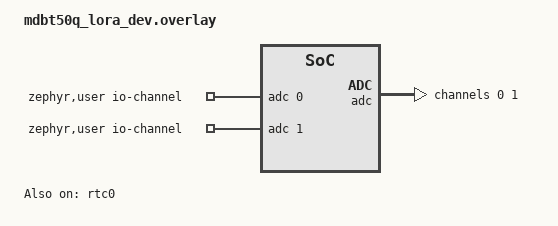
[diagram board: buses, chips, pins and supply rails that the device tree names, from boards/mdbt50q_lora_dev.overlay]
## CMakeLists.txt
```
cmake_minimum_required(VERSION 3.20.0)

find_package(Zephyr REQUIRED HINTS $ENV{ZEPHYR_BASE})
project(nrf52840_rtos_6sens)

FILE(GLOB app_sources src/*.c)
target_sources(app PRIVATE ${app_sources})
```

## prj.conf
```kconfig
# Debugger Support
CONFIG_UART_CONSOLE=n
CONFIG_CONSOLE=y
CONFIG_SERIAL=y

# RTT Segger Support
CONFIG_RTT_CONSOLE=y
CONFIG_USE_SEGGER_RTT=y
CONFIG_LOG_BACKEND_RTT=y

# Communication Bus Support
CONFIG_GPIO=y
CONFIG_SPI=y
CONFIG_I2C=y

# Hardware Support
CONFIG_ADC=y
CONFIG_SENSOR=y

# RTC Support
CONFIG_RTC=y
CONFIG_COUNTER=y
CONFIG_CLOCK_CONTROL=y
CONFIG_COUNTER_MAXIM_DS3231=y

# LoRa Support
CONFIG_LORA=y

# LoRaWAN Support
CONFIG_LORAWAN=y
CONFIG_HAS_SEMTECH_LORAMAC=y
CONFIG_LORAMAC_REGION_EU868=y
CONFIG_LORAWAN_SYSTEM_MAX_RX_ERROR=100

# Flash Memory Support (MX25R64 and partion flash memory of MDBT50Q)
# Flash Memory Support
CONFIG_FLASH=y
CONFIG_FLASH_MAP=y
CONFIG_MPU_ALLOW_FLASH_WRITE=y
CONFIG_NORDIC_QSPI_NOR=y

# Stack Support
CONFIG_MAIN_STACK_SIZE=2048
CONFIG_SYSTEM_WORKQUEUE_STACK_SIZE=2048

# Random Number Generation Support
CONFIG_TEST_RANDOM_GENERATOR=y
CONFIG_PRINTK=y
CONFIG_CBPRINTF_FP_SUPPORT=y
CONFIG_NEWLIB_LIBC=y
CONFIG_NEWLIB_LIBC_FLOAT_PRINTF=y
CONFIG_FP_SOFTABI=y
```

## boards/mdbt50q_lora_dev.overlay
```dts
/*
 * Copyright (c) 2025
 * Regis Rousseau
 * Univ Lyon, INSA Lyon, Inria, CITI, EA3720
 * SPDX-License-Identifier: Apache-2.0
 */

/* VBAT battery voltage monitoring and Sismic sensor analog value conversion */
/ {
	zephyr,user {
		io-channels = <&adc 0>,<&adc 1>;
	};
};

/* enable the corresponding ADC, with the correct configuration */
&adc {
	#address-cells = <1>;
	#size-cells = <0>;
	status = "okay";

	/* external ADC channnel AIN0 of MDBT50Q, Port P0.02 on schematic for geophone*/
	channel@0 {
		reg = <0>;											/* channel 0 of the ADC */
		zephyr,gain = "ADC_GAIN_1_6";						/* attenuated by 6 (x1/6) */
		zephyr,reference = "ADC_REF_INTERNAL";				/* reference voltage +0.6 */
		zephyr,acquisition-time = <ADC_ACQ_TIME_DEFAULT>;	/* 10us */
		zephyr,input-positive = <NRF_SAADC_AIN0>;			/* P0.02 for nRF52xx */
		zephyr,resolution = <12>;
	};
	
	/* external ADC channnel AIN1 of MDBT50Q, Port P0.03 on schematic for battery*/
	channel@1 {
		reg = <1>;											/* channel 0 of the ADC */
		zephyr,gain = "ADC_GAIN_1_6";						/* attenuated by 6 (x1/6) */
		zephyr,reference = "ADC_REF_INTERNAL";				/* reference voltage +0.6 */
		zephyr,acquisition-time = <ADC_ACQ_TIME_DEFAULT>;	/* 10us */
		zephyr,input-positive = <NRF_SAADC_AIN1>;			/* P0.03 for nRF52xx */
		zephyr,resolution = <12>;
	};
};

&rtc0 {
	status = "okay";
};
```

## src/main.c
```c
/*
 * Copyright (c) 2025
 * Regis Rousseau
 * Univ Lyon, INSA Lyon, Inria, CITI, EA3720
 * SPDX-License-Identifier: Apache-2.0
 */

//  ========== includes ====================================================================
#include <zephyr/kernel.h>
#include "app_sensors.h"
#include "app_adc.h"
#include "app_eeprom.h"
#include "app_rtc.h"
#include <stdbool.h>
#include <stdio.h>

//  ========== defines =====================================================================
#define STACK_SIZE			2048
#define PRIORITY_RTC		2
#define PRIORITY_LORAWAN	3

//  ========== globals =====================================================================
// define GPIO specifications for the LEDs used to indicate transmission (TX) and reception (RX)
static const struct gpio_dt_spec led_tx = GPIO_DT_SPEC_GET(LED_TX, gpios);
static const struct gpio_dt_spec led_rx = GPIO_DT_SPEC_GET(LED_RX, gpios);

static void dl_callback(uint8_t port, bool data_pending,
			int16_t rssi, int8_t snr,
			uint8_t len, const uint8_t *hex_data)
{
	printk("Port %d, Pending %d, RSSI %ddB, SNR %ddBm\n", port, data_pending, rssi, snr);
}

// thread to have a periodic sync
bool rtc_thread_flag = true;
void rtc_thread_func(void)
{
	printk("periodic sync thread started\n");

	const struct device *rtc_dev = DEVICE_DT_GET(DT_NODELABEL(rtc0));
	const struct device *ds3231_dev = DEVICE_DT_GET_ONE(maxim_ds3231);

	while (rtc_thread_flag == true) {
        printk("performing periodic action\n");
        //(void)app_rtc_periodic_sync(rtc_dev);
		(void)app_ds3231_periodic_sync(ds3231_dev);
        k_sleep(K_SECONDS(60));		
	}
}
K_THREAD_DEFINE(rtc_thread_id, STACK_SIZE, rtc_thread_func, NULL, NULL, NULL, PRIORITY_RTC, 0, 0);

// thread to send environment value when no activity
bool lorawan_thread_flag = true;
void lorawan_thread_func(void)
{
	printk("LoRaWAN thread started\n");
    while (lorawan_thread_flag == true) {
        printk("performing periodic action\n");
		// perform your task: get battery level, temperature and humidity
        (void)app_sensors_handler();	
        k_sleep(K_SECONDS(60));		// sleep for 1 min -> test
    }
}
K_THREAD_DEFINE(lorawan_thread_id, STACK_SIZE, lorawan_thread_func, NULL, NULL, NULL, PRIORITY_LORAWAN, 0, 0);

static void lorwan_datarate_changed(enum lorawan_datarate dr)
{
	uint8_t unused, max_size;

	lorawan_get_payload_sizes(&unused, &max_size);
	printk("New Datarate: DR_%d, Max Payload %d\n", dr, max_size);
}

//  ========== main ========================================================================
int8_t main(void)
{
	const struct device *dev;
	int8_t ret;

	printk("Initializtion of all Hardware Devices\n");

	// initialize ADC device
	ret = app_nrf52_adc_init();
	if (ret != 1) {
		printk("failed to initialize ADC device\n");
		return 0;
	}

	// initialize partition flash memory
	ret = app_flash_init();
	if (ret != 1) {
		printk("failed to initialize internal Flash device\n");
		return 0;
	}

	// initialize the EEPROM device
	const struct device *eeprom_dev = DEVICE_DT_GET(SPI_FLASH_DEVICE);
	ret = app_eeprom_init(eeprom_dev);
	if (ret != 1) {
		printk("failed to initialize QSPI flash device\n");
		return 0;
	}

	// initialize DS3231 RTC device via I2C (Pins: SDA -> P0.09, SCL -> P0.0)
	const struct device *rtc_dev = app_rtc_init();
    if (!rtc_dev) {
        printk("failed to initialize RTC device\n");
        return 0;
    }

	// initialize LoRaWAN protocol and register the device
	const struct device *lora_dev;
	struct lorawan_join_config join_cfg;
	uint8_t dev_eui[] = LORAWAN_DEV_EUI;
	uint8_t join_eui[] = LORAWAN_JOIN_EUI;
	uint8_t app_key[] = LORAWAN_APP_KEY;

	struct lorawan_downlink_cb downlink_cb = {
		.port = LW_RECV_PORT_ANY,
		.cb = dl_callback
	};

	lora_dev = DEVICE_DT_GET(DT_ALIAS(lora0));
	if (!device_is_ready(lora_dev)) {
		printk("%s: device not ready\n", lora_dev->name);
		return 0;
	}

	ret = lorawan_start();
	if (ret < 0) {
		printk("lorawan_start failed: %d", ret);
		return 0;
	}

	lorawan_register_downlink_callback(&downlink_cb);
	lorawan_register_dr_changed_callback(lorwan_datarate_changed);

	join_cfg.mode = LORAWAN_ACT_OTAA;
	join_cfg.dev_eui = dev_eui;
	join_cfg.otaa.join_eui = join_eui;
	join_cfg.otaa.app_key = app_key;
	join_cfg.otaa.nwk_key = app_key;
	join_cfg.otaa.dev_nonce = 0u;

	printk("Joining network over OTAA\n");
	ret = lorawan_join(&join_cfg);
	if (ret < 0) {
		printk("lorawan_join_network failed: %d\n", ret);
		return 0;
	}

	printk("Geophone Measurement and Process Information\n");

	// enable environmental sensor and battery level thread
	lorawan_thread_flag = false;

	// enable periodic rtc sync thread
	rtc_thread_flag = true;

	// start ADC sampling and STA/LTA threads
	app_adc_sampling_start();
  app_sta_lta_start();
	return 0;
}
```

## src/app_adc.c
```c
/*
 * Copyright (c) 2025
 * Regis Rousseau
 * Univ Lyon, INSA Lyon, Inria, CITI, EA3720
 * SPDX-License-Identifier: Apache-2.0
 */

#include "app_adc.h"

//  ========== globals =====================================================================
// ADC buffer to store raw ADC readings
static int16_t buffer1;
static int16_t buffer0;
static uint16_t ring_buffer[ADC_BUFFER_SIZE];
static uint32_t sampling_rate_ms = SAMPLING_RATE_MS;
static bool stop_sampling = false;
static bool adc_initialized = false;

// ADC channel configuration obtained from the device tree
static const struct adc_dt_spec adc_channel = ADC_DT_SPEC_GET(DT_PATH(zephyr_user));
static struct adc_sequence sequence0, sequence1;

// define a stack for the ADC thread, with a size of 1024 bytes
K_THREAD_STACK_DEFINE(adc_stack, 1024);

// structure to hold ADC thread data
struct k_thread adc_thread_data;

// mutex to manage concurrent access to the ADC ring buffer
K_MUTEX_DEFINE(buffer_lock);

// mutex to manage access to buffers when retrieving ADC data
K_MUTEX_DEFINE(get_buffer_lock);

// semaphore to signal when new ADC data is available
K_SEM_DEFINE(data_ready_sem, 0, 1);

// semaphore to signal sampling rate change
K_SEM_DEFINE(rate_change_sem, 0, 1);

// define a ring buffer to store ADC samples
static uint16_t ring_buffer[ADC_BUFFER_SIZE];

// index to track the head of the ring buffer
int ring_head = 0;

// configure ADC sequence
static int8_t configure_adc_sequence(struct adc_sequence *sequence, uint8_t channel_bitmask, void *buffer, size_t buffer_size) {
    sequence->channels = BIT(channel_bitmask);
    sequence->buffer = buffer;
    sequence->buffer_size = buffer_size;
    return adc_sequence_init_dt(&adc_channel, sequence);
}

//  ========== app_nrf52_adc_init ==========================================================
int8_t app_nrf52_adc_init()
{
    if (adc_initialized) {
        printk("ADC is already initialized\n");
        return 0;
    }

   if (!adc_is_ready_dt(&adc_channel)) {
        printk("ADC is not ready. Check hardware configuration.\n");
        return -1;
    }

    int8_t err = adc_channel_setup_dt(&adc_channel);
    if (err < 0) {
        printk("failed to setup ADC channel. Error: %d\n", err);
        return err;
    }

    if (configure_adc_sequence(&sequence0, 0, &buffer0, sizeof(buffer0)) < 0 ||
        configure_adc_sequence(&sequence1, 1, &buffer1, sizeof(buffer1)) < 0) {
        printk("failed to configure ADC sequences\n");
        return -1;
    }

    adc_initialized = true;
    printk("ADC initialized successfully\n");
    return 1;
}

//  ========== app_nrf52_get_ain1 ==========================================================
int16_t app_nrf52_get_ain1()
{
    int16_t percent;

    // read sample from the ADC
    if (adc_read(adc_channel.dev, &sequence1) < 0) {        
	    printk("failed to read ADC sequence 1.\n");
	    return 0;
    }

    // convert ADC reading to voltage
    int32_t voltage = (buffer1 * ADC_REFERENCE_VOLTAGE) / ADC_RESOLUTION;
    printk("convert voltage: %d mV\n", voltage);

    // ensure voltage is within range
    if (voltage > BATTERY_MAX_VOLTAGE) voltage = BATTERY_MAX_VOLTAGE;
    if (voltage < BATTERY_MIN_VOLTAGE) voltage = BATTERY_MIN_VOLTAGE + 1;
    printk("clamped voltage: %d mV\n", voltage);

    // non-linear scaling
    int32_t range = BATTERY_MAX_VOLTAGE - BATTERY_MIN_VOLTAGE;
    int32_t difference = voltage - BATTERY_MIN_VOLTAGE;

    if (range > 0 && difference > 0) {
        // use power scaling: percentage = ((difference / range) ^ 1.5) * 100
        double normalized = (double)difference / range;  // normalize to range [0, 1]
        double scaled = pow(normalized, 1.2);            // apply non-linear scaling
        percent = (int16_t)(scaled * 100);               // convert to percentage
    } else {
        printk("error: invalid range or difference.\n");
        percent = 0;
    }

    printk("battery level (non-linear): %d%%\n", percent);
    return percent;
}

//  ========== app_adc_thread ==============================================================
static void app_adc_thread(void *arg1, void *arg2, void *arg3)
{
    while (!stop_sampling) {
        if (adc_read(adc_channel.dev, &sequence0) == 0) {
            k_mutex_lock(&buffer_lock, K_FOREVER);
            ring_buffer[ring_head] = buffer0;
            ring_head = (ring_head + 1) % ADC_BUFFER_SIZE;
            k_mutex_unlock(&buffer_lock);
            k_sem_give(&data_ready_sem);
        } else {
            printk("failed to read ADC sequence 0\n");
        }

        // check for a rate change signal
        if (k_sem_take(&rate_change_sem, K_NO_WAIT) == 0) {
            printk("sampling rate updated to %d ms\n", sampling_rate_ms);
            k_sem_reset(&rate_change_sem);  // reset semaphore count
        }
        k_sleep(K_MSEC(sampling_rate_ms));
    }
}

//  ========== adc_sampling_start and stop  ================================================
// start the ADC sampling thread
// the thread reads data from the ADC and stores it in a ring buffer
void app_adc_sampling_start(void)
{
    stop_sampling = false;
    k_thread_create(&adc_thread_data, adc_stack, K_THREAD_STACK_SIZEOF(adc_stack),
                    app_adc_thread, NULL, NULL, NULL, 1, 0, K_NO_WAIT);
    //printk("ADC sampling thrad started\n");
}

// stop ADC sampling thread
void app_adc_sampling_stop(void)
{
    stop_sampling = true;
    k_sem_give(&rate_change_sem); // interrupt sleep if needed
    k_thread_join(&adc_thread_data, K_FOREVER);
    //printk("ADC sampling thread stopped.\n");
}

//  ========== adc_get_buffer ==============================================================
// copie a portion of the ADC ring buffer to a user-supplied buffer.
// use a mutex to ensure thread-safe access.
void app_adc_get_buffer(uint16_t *dest, size_t size, int offset)
{
    if (!dest || size > ADC_BUFFER_SIZE) {
        printk("invalid parameters in adc_get_buffer.\n");
        return;
    }

    // handle negative offsets by wrapping them around the buffer
    int start_index = (ring_head + offset + ADC_BUFFER_SIZE) % ADC_BUFFER_SIZE;

    //printk("fetching ADC buffer: start_index=%d, size=%zu\n", start_index, size);

    k_mutex_lock(&buffer_lock, K_FOREVER);
    // for (int i = 0; i < 10; i++) {  // Print first 10 entries
    //     printk("ring_buffer[%d]: %d\n", i, ring_buffer[i]);
    // }

    for (size_t i = 0; i < size; i++) {
        dest[i] = ring_buffer[(start_index + i) % ADC_BUFFER_SIZE];
        //printk("dest[%zu] = ring_buffer[%d] = %d\n", i, (start_index + i) % ADC_BUFFER_SIZE, dest[i]);
    }
    k_mutex_unlock(&buffer_lock);
}

// set ADC sampling rate
void app_adc_set_sampling_rate(uint32_t rate_ms)
{
    sampling_rate_ms = rate_ms;
    k_sem_give(&rate_change_sem);  // signal the thread about the rate change
    //printk("sampling rate set to %d ms.\n", rate_ms);
}
```

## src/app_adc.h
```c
/*
 * Copyright (c) 2025
 * Regis Rousseau
 * Univ Lyon, INSA Lyon, Inria, CITI, EA3720
 * SPDX-License-Identifier: Apache-2.0
 */

#ifndef APP_ADC_H
#define APP_ADC_H

//  ========== includes ====================================================================
#include <zephyr/kernel.h>
#include <zephyr/device.h>
#include <zephyr/devicetree.h>
#include <zephyr/drivers/adc.h>
#include <stdint.h>
#include <stdio.h>
#include <stddef.h>

//  ========== defines =====================================================================
#define ADC_REFERENCE_VOLTAGE       3300    // 3.3V reference voltage of the board
#define ADC_RESOLUTION              4096    // 12-bit resolution
#define ADC_BUFFER_SIZE             1024     
#define SAMPLING_RATE_MS            10
#define BATTERY_MAX_VOLTAGE         2980
#define BATTERY_MIN_VOLTAGE         2270

//  ========== globals =====================================================================
extern struct k_sem data_ready_sem;
extern int ring_head;

//  ========== prototypes ==================================================================
int8_t app_nrf52_adc_init();
int16_t app_nrf52_get_ain1();
void app_adc_sampling_start(void);
void app_adc_sampling_stop(void);
void app_adc_get_buffer(uint16_t *dest, size_t size, int offset);
void app_adc_set_sampling_rate(uint32_t rate_ms);

#endif /* APP_ADC_H */
```

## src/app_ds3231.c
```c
/*
 * Copyright (c) 2025
 * Regis Rousseau
 * Univ Lyon, INSA Lyon, Inria, CITI, EA3720
 * SPDX-License-Identifier: Apache-2.0
 */

//  ========== includes ==================================================================
#include "app_ds3231.h"

//  ========== globals ===================================================================
static int64_t system_rtc_offset_ms = 0;
static struct k_mutex offset_mutex;

//  ========== bcd_to_bin ================================================================ 
static uint8_t bcd_to_bin(uint8_t val)
{
    return ((val >> 4) * 10) + (val & 0x0F);
}

// ========== bin_to_bcd =================================================================
static uint8_t bin_to_bcd(uint8_t val)
{
    return ((val / 10) << 4) | (val % 10);
}

//  ========== et_ds3231_from_unix_time ==================================================
void set_ds3231_from_unix_time(const struct device *rtc_dev, int64_t unix_time)
{
    struct tm tm;
    time_t t = (time_t)unix_time;
    gmtime_r(&t, &tm);  
    //timeutil_localtime64(unix_time, &tm);
    ds3231_set_time(rtc_dev, &tm);
}

// ========== ds3231_set_time ============================================================
int8_t ds3231_set_time(const struct device *i2c_dev, const struct tm *tm)
{
    uint8_t time_buf[7];
    int8_t ret;

    if (!i2c_dev || !tm) {
        return -EINVAL;
    }

    time_buf[0] = bin_to_bcd(tm->tm_sec);
    time_buf[1] = bin_to_bcd(tm->tm_min);
    time_buf[2] = bin_to_bcd(tm->tm_hour);
    time_buf[3] = bin_to_bcd(tm->tm_wday + 1);         // struct tm: 0=Sun → DS3231: 1=Sun
    time_buf[4] = bin_to_bcd(tm->tm_mday);
    time_buf[5] = bin_to_bcd(tm->tm_mon + 1);          // struct tm: 0=Jan → DS3231: 1=Jan
    time_buf[6] = bin_to_bcd(tm->tm_year - 100);       // struct tm: years since 1900 → DS3231: years since 2000

    ret = i2c_burst_write(i2c_dev, DS3231_I2C_ADDR, DS3231_REG_TIME, time_buf, sizeof(time_buf));
    if (ret < 0) {
        printk("failed to write time to DS3231: %d\n", ret);
        return ret;
    }

    printk("DS3231 time set successfully\n");
    return 0;
}

//  ========== ds3231_get_time ================================================================ 
int8_t ds3231_get_time(const struct device *i2c_dev, struct tm *tm)
{
    uint8_t time_buf[7];
    int8_t ret;

    if (!i2c_dev || !tm) {
        return -EINVAL;
    }

    ret = i2c_burst_read(i2c_dev, DS3231_I2C_ADDR, DS3231_REG_TIME, time_buf, sizeof(time_buf));
    if (ret < 0) {
        printk("failed to read DS3231 registers. error: %d", ret);
        return ret;
    }

    tm->tm_sec  = bcd_to_bin(time_buf[0] & 0x7F);
    tm->tm_min  = bcd_to_bin(time_buf[1] & 0x7F);
    tm->tm_hour = bcd_to_bin(time_buf[2] & 0x3F);  // 24-hour format
    tm->tm_wday = bcd_to_bin(time_buf[3] & 0x07) - 1;  // DS3231: 1=Sun...7=Sat → struct tm: 0=Sun...6=Sat
    tm->tm_mday = bcd_to_bin(time_buf[4] & 0x3F);
    tm->tm_mon  = bcd_to_bin(time_buf[5] & 0x1F) - 1;  // struct tm: 0=Jan
    tm->tm_year = bcd_to_bin(time_buf[6]) + 100;       // since 1900 → 2000 + xx

    return 0;
}

//  ========== app_rtc_init ================================================================
const struct device *app_ds3231_init(void)
{
    const struct device *i2c_dev = DEVICE_DT_GET_ONE(maxim_ds3231);
    if (!i2c_dev) {
        printk("no DS3231 device found\n");
        return NULL;
    }

    // initialize mutex
    k_mutex_init(&offset_mutex);

    printk("DS3231 initialized and started successfully (device: %s)\n", i2c_dev->name);
    return i2c_dev;
}

//  ========== app_ds3231_sync_uptime ========================================================
// synchronize the system uptime with the DS3231 RTC
int8_t app_ds3231_sync_uptime(const struct device *i2c_dev)
{
    if (!i2c_dev) {
        printk("DS3231 device is NULL\n");
        return -EINVAL;
    }

    struct tm rtc_tm;
    int64_t rtc_epoch_s;
    int64_t rtc_epoch_ms;
    int64_t current_uptime_ms;
    int64_t new_offset_ms;

    // get time from external RTC
    if (ds3231_get_time(i2c_dev, &rtc_tm) != 0) {
        printk("failed to read time from DS3231\n");
        return -EIO;
    }

    // calculate the offset between RTC time and system uptime
    rtc_epoch_s = timeutil_timegm64(&rtc_tm);
    rtc_epoch_ms = rtc_epoch_s * 1000;
    current_uptime_ms = k_uptime_get();
    new_offset_ms = rtc_epoch_ms - current_uptime_ms;

    // safely update the global offset
    k_mutex_lock(&offset_mutex, K_FOREVER);
    system_rtc_offset_ms = new_offset_ms;
    k_mutex_unlock(&offset_mutex);

    // debugging output
    printk("synced: DS3231 epoch_ms = %lld, uptime = %lld, offset = %lld\n",
           rtc_epoch_ms, current_uptime_ms, new_offset_ms);

    return 0;
}

//  ========== app_rtc_get_time ==========================================================
uint64_t app_ds3231_get_time()
{
    int64_t now_ms = k_uptime_get();
    int64_t offset;

    k_mutex_lock(&offset_mutex, K_FOREVER);
    offset = system_rtc_offset_ms;
    k_mutex_unlock(&offset_mutex);

    // protect against overflow
    if (offset > 0 && now_ms > UINT64_MAX - offset) {
        return UINT64_MAX;
    }
    if (offset < 0 && now_ms < (uint64_t)(-offset)) {
        return 0;
    }
    uint64_t timestamp_ms = now_ms + offset;
    return timestamp_ms;
}

//  ========== app_ds3231_periodic_sync====================================================
int8_t app_ds3231_periodic_sync(const struct device *i2c_dev)
{
    if (!i2c_dev) {
        printk("RTC device is NULL\n");
        return -EINVAL;
    }
    
    // call this periodically from a thread or workqueue
    int ret = app_ds3231_sync_uptime(i2c_dev);
    if (ret < 0) {
        printk("periodic sync failed, error: %d", ret);
    }
    return 0;
}
```

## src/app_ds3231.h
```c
/*
 * Copyright (c) 2025
 * Regis Rousseau
 * Univ Lyon, INSA Lyon, Inria, CITI, EA3720
 * SPDX-License-Identifier: Apache-2.0
 */

#ifndef APP_DS3231_H
#define APP_DS3231_H

//  ========== includes ====================================================================
#include <zephyr/kernel.h>
#include <zephyr/device.h>
#include <zephyr/devicetree.h>
#include <zephyr/drivers/rtc.h>
#include <zephyr/drivers/counter.h>
#include <zephyr/drivers/i2c.h>
#include <zephyr/sys_clock.h>
#include <time.h>

//  ========== defines =====================================================================
#define ONE_YEAR_MS         31536000000LL
#define DS3231_I2C_ADDR     0x68
#define DS3231_REG_TIME     0x00

//  ========== prototypes ===================================================================
const struct device *app_ds3231_init(void);
int8_t  app_ds3231_sync_uptime(const struct device *i2c_dev);
uint64_t app_ds3231_get_time();
int8_t app_ds3231_periodic_sync(const struct device *i2c_dev);
int8_t ds3231_set_time(const struct device *i2c_dev, const struct tm *tm);
int8_t ds3231_get_time(const struct device *i2c_dev, struct tm *tm);
void set_ds3231_from_unix_time(const struct device *rtc_dev, int64_t unix_time);

#endif /* APP_DS3231_H */
```

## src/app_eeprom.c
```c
/*
 * Copyright (c) 2025
 * Regis Rousseau
 * Univ Lyon, INSA Lyon, Inria, CITI, EA3720
 * SPDX-License-Identifier: Apache-2.0
 */

#include "app_eeprom.h"
#include "app_rtc.h"

//  ========== app_eeprom_init =============================================================
int8_t app_eeprom_init(const struct device *dev)
{
	int8_t ret = 0;
	ssize_t size, page;

	// getting EEPROM size
	dev = DEVICE_DT_GET(SPI_FLASH_DEVICE);
	if (dev == NULL) {
		printk("no eeprom device found. error: %d\n", dev);
		return 0;
	}
	
	if (!device_is_ready(dev)) {
		printk("eeprom is not ready\n");
		return 0;
	} else {
        printk("- found device \"%s\"\n", dev->name);
    }
	return 1;
}

//  ========== app_eeprom_write ============================================================
int8_t app_eeprom_write(const struct device *dev, int16_t data)
{
	int8_t ret = 0;
	
	// writing data in the first page of 4kbytes
	ret = eeprom_write(dev, SPI_FLASH_OFFSET, &data, sizeof(data));
	if (ret!=0) {
		printk("error writing data. error: %d\n", ret);
	} else {
	//	printk("wrote %zu bytes to address 0x00\n", sizeof(data));
	}
	// printing data
	printk("write -> rom val: %d\n", data);
	return 0;
}

//  ========== app_rom_read ================================================================
int16_t* app_eeprom_read(const struct device *dev)
{
	int8_t ret = 0;
	int16_t data[MAX_RECORDS];

	// reading the first page
	ret = eeprom_read(dev, SPI_FLASH_OFFSET, &data, sizeof(data));
	if (ret) {
		printk("error reading data. error: %d\n", ret);
	} else {
	//	printk("read %zu bytes from address 0x00\n", sizeof(data));
	}

	// reading data
	for (int8_t i = 0; i < MAX_RECORDS; i++) {
		printk("read -> rom val: %d\n", data[i]);
	}
	return data;
}
```

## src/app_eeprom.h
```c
/*
 * Copyright (c) 2025
 * Regis Rousseau
 * Univ Lyon, INSA Lyon, Inria, CITI, EA3720
 * SPDX-License-Identifier: Apache-2.0
 */

#ifndef APP_EEPROM_H
#define APP_EEPROM_H

//  ========== includes ====================================================================
#include <zephyr/kernel.h>
#include <zephyr/device.h>
#include <zephyr/devicetree.h>
#include <zephyr/drivers/eeprom.h>

//  ========== defines =====================================================================
#define SPI_FLASH_DEVICE        DT_COMPAT_GET_ANY_STATUS_OKAY(nordic_qspi_nor)
#define SPI_FLASH_OFFSET		0x00000
#define MAX_RECORDS             65534   // samples (2 bytes) + timestamp (4 bytes)                   

//  ========== prototypes ==================================================================
int8_t app_eeprom_init(const struct device *dev);
int8_t app_eeprom_write(const struct device *dev, int16_t data);
int16_t* app_eeprom_read(const struct device *dev);

#endif /* APP_EEPROM_H */
```

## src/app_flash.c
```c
/*
 * Copyright (c) 2025
 * Regis Rousseau
 * Univ Lyon, INSA Lyon, Inria, CITI, EA3720
 * SPDX-License-Identifier: Apache-2.0
 */

//  ========== includes ====================================================================
#include "app_adc.h"
#include "app_sht31.h"
#include "app_flash.h"

//  ========== globals =====================================================================
struct flash_header {
    uint32_t magic;
    uint32_t head;
};

//  ========== app_flash_init ==============================================================
int8_t app_flash_init()
{
	const struct flash_area *fa;
	int8_t  ret = flash_area_open(FIXED_PARTITION_ID(storage_partition), &fa);
	if (ret != 0) {
    	printk("Failed to open flash area\n");
    	return -1;
	}
	
	struct flash_header hdr;
	flash_area_read(fa, FLASH_HEAD_OFFSET, &hdr, sizeof(hdr));

	if (hdr.magic != MAGIC_KEY) {
		printk("flash not initialized. initializing now.\n");

		// Erase first sector
		flash_area_erase(fa, FLASH_HEAD_OFFSET, FLASH_SECTOR_SIZE);

		// Write new header
		hdr.magic = MAGIC_KEY;
		hdr.head = 0;
		flash_area_write(fa, FLASH_HEAD_OFFSET, &hdr, sizeof(hdr));
	} else {
		printk("flash already initialized. Head: %u\n", hdr.head);
	}
	flash_area_close(fa);
	return 1;
}

//  ========== app_flash_store =============================================================
int8_t app_flash_store(const struct vth *data)
{
    const struct flash_area *fa;
    int8_t ret = flash_area_open(FIXED_PARTITION_ID(storage_partition), &fa);
    if (ret != 0) {
        printk("failed to open flash area\n");
        return -1;
    }

    // read head from the head sector
    uint32_t head = 0;
    flash_area_read(fa, 0, &head, sizeof(head));  // head at offset 0

    // compute current data offset
    uint32_t index = head % MAX_RECORDS;
    off_t data_offset = FLASH_DATA_OFFSET + index * RECORD_SIZE;

    // erase sector only when writing first record of a sector
	uint32_t records_per_sector = FLASH_SECTOR_SIZE / RECORD_SIZE;
	if ((index % records_per_sector) == 0) {
		off_t sector_offset = data_offset & ~(FLASH_SECTOR_SIZE - 1);
		ret = flash_area_erase(fa, sector_offset, FLASH_SECTOR_SIZE);
		if (ret != 0) {
			printk("erase failed at offset 0x%x\n", (uint32_t)sector_offset);
			flash_area_close(fa);
			return -1;
		}
	}

    // write record
    ret = flash_area_write(fa, data_offset, data, RECORD_SIZE);
    if (ret != 0) {
        printk("write failed at offset 0x%x\n", (uint32_t)data_offset);
        flash_area_close(fa);
        return -1;
    }

    // Update head
    head = (head + 1) % MAX_RECORDS;
    flash_area_write(fa, 0, &head, sizeof(head));
    if (ret != 0) {
		printk("failed to update head\n");
		flash_area_close(fa);
		return -1;
	}
    flash_area_close(fa);
    return 0;
}

//  ========== app_flash_handler ===========================================================
int8_t app_flash_handler(const struct device *dev)
{
	struct vth data;

	// retrieve the sensor device using the device tree API
	if (!device_is_ready(dev)) {
        printk("%s: sensor device not ready\n", dev->name);
        return -1;
    }

	// collect sensor data until the maximum number of records is reached
	// measure and store the battery voltage
	data.vbat = app_nrf52_get_vbat();

	// measure and store the temperature using the SHT31 sensor
	data.temp = app_sht31_get_temp(dev);

	k_msleep(5000);		// small delay  between reading the temperature and humidity values

	// measure and store the humidity using the SHT31 sensor
	data.hum = app_sht31_get_hum(dev);

	// save the collected sensor data into the flash memory
	int8_t ret = app_flash_store(&data);
    return 1;
}
```

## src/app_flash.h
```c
/*
 * Copyright (c) 2025
 * Regis Rousseau
 * Univ Lyon, INSA Lyon, Inria, CITI, EA3720
 * SPDX-License-Identifier: Apache-2.0
 */

#ifndef APP_FLASH_H
#define APP_FLASH_H

//  ========== includes ====================================================================
#include <zephyr/kernel.h>
#include <zephyr/device.h>
#include <zephyr/devicetree.h>
#include <zephyr/drivers/flash.h>
#include <zephyr/storage/flash_map.h>

//  ========== globals =====================================================================
struct vth {
	int16_t vbat;
	int16_t temp;
	int16_t hum;
};

//  ========== defines =====================================================================
#define FLASH_PARTITION_OFFSET  0x000F8000	
#define FLASH_SECTOR_SIZE       4096		// one flash page = 4 KB		
#define FLASH_SECTOR_COUNT      4			// 4 sectors × 4 KB = 16 KB
#define FLASH_TOTAL_SIZE        (FLASH_SECTOR_SIZE * FLASH_SECTOR_COUNT)

#define FLASH_HEAD_OFFSET		0x0000                 
#define FLASH_DATA_OFFSET       0x0100

#define MAX_RECORDS             (0x8000 - FLASH_DATA_OFFSET) / RECORD_SIZE  // = 4064
#define RECORD_SIZE             8 
#define MAGIC_KEY				0xDEADBEEF

//  ========== prototypes ==================================================================
int8_t app_flash_init(void);
int8_t app_flash_store(const struct vth *data);
int8_t app_flash_handler(const struct device *dev);

#endif /* APP_FLASH_H */
```

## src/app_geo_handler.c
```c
/*
 * Copyright (c) 2025
 * Regis Rousseau
 * Univ Lyon, INSA Lyon, Inria, CITI, EA3720
 * SPDX-License-Identifier: Apache-2.0
 */

#include "app_geo_handler.h"

//  ========== globals =====================================================================
// circular buffer for ADC data
volatile uint16_t adcBuffer[BUFFER_SIZE];
volatile uint16_t bufferIndex = 0;

//  ========== app_adc_callback() ==========================================================
int8_t app_adc_callback(uint16_t sample)
{
	    // called by ADC interrupt or DMA
		adcBuffer[bufferIndex] = sample;
		bufferIndex = (bufferIndex + 1) % BUFFER_SIZE;
}

//  ========== app_int8_t app_send_to_lorawan ==============================================
int8_t app_send_to_lorawan(uint16_t *data, size_t length)
{
	int8_t ret;

	ret = lorawan_send(LORAWAN_PORT, data, length, LORAWAN_MSG_CONFIRMED);

    if (ret == -EAGAIN) {
        printk("lorawan_send failed: %d. continuing...\n", ret);
        return 0;
    }
    
    if (ret < 0) {
        printk("lorawan_send failed. error: %d.\n", ret);
        return 0;
    } else {
        printk("data sent!\n");
    }
}

//  ========== app_geo_handler =============================================================
int8_t app_geo_handler()
{
	static uint32_t staSum = 0;
    static uint32_t ltaSum = 0;
    static size_t staCount = 0;
    static size_t ltaCount = 0;
    static uint16_t processedIndex = 0;

    // process new samples since the last run
    while (processedIndex != bufferIndex) {
        uint16_t sample = adcBuffer[processedIndex];
        processedIndex = (processedIndex + 1) % BUFFER_SIZE;

        // update STA and LTA
        staSum += sample;
        ltaSum += sample;
        staCount++;
        ltaCount++;

        if (staCount > STA_WINDOW) {
            staSum -= adcBuffer[(processedIndex - STA_WINDOW + BUFFER_SIZE) % BUFFER_SIZE];
            staCount--;
        }

        if (ltaCount > LTA_WINDOW) {
            ltaSum -= adcBuffer[(processedIndex - LTA_WINDOW + BUFFER_SIZE) % BUFFER_SIZE];
            ltaCount--;
        }

        // calculate STA/LTA ratio
        if (staCount >= STA_WINDOW && ltaCount >= LTA_WINDOW) {
            float sta = (float)staSum / STA_WINDOW;
            float lta = (float)ltaSum / LTA_WINDOW;

            if (lta > 0 && (sta / lta) > THRESHOLD) {
                // trigger detection event
                size_t detectionLength = STA_WINDOW + LTA_WINDOW;
                uint16_t detectionData[detectionLength];
                for (size_t i = 0; i < detectionLength; i++) {
                    detectionData[i] = adcBuffer[(processedIndex - detectionLength + i + BUFFER_SIZE) % BUFFER_SIZE];
                }
                app_send_to_lorawan(detectionData, detectionLength);
            }
        }
    }
	return 0;
}
```

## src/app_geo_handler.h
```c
/*
 * Copyright (c) 2025
 * Regis Rousseau
 * Univ Lyon, INSA Lyon, Inria, CITI, EA3720
 * SPDX-License-Identifier: Apache-2.0
 */

#ifndef APP_GEO_HANDLER_H
#define APP_GEO_HANDLER_H

//  ========== includes ====================================================================
#include "app_adc.h"
#include "app_eeprom.h"
#include "app_rtc.h"
#include "app_lorawan.h"

//  ========== defines =====================================================================
#define BUFFER_SIZE        1000
#define STA_WINDOW          10
#define LTA_WINDOW          100
#define THRESHOLD           3.0

//  ========== prototypes ==================================================================
int8_t app_send_to_lorawan(uint16_t *data, size_t length);
int8_t app_geo_handler();
int8_t app_adc_callback(uint16_t sample);

#endif /* APP_SHT31_ADC_HANDLER_H */
```

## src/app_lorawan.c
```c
/*
 * Copyright (c) 2025
 * Regis Rousseau
 * Univ Lyon, INSA Lyon, Inria, CITI, EA3720
 * SPDX-License-Identifier: Apache-2.0
 */

//  ========== includes ====================================================================
#include "app_lorawan.h"
#include "app_flash.h"

//  ========== globals =====================================================================
static const struct gpio_dt_spec led_tx = GPIO_DT_SPEC_GET(LED_TX, gpios);
static const struct gpio_dt_spec led_rx = GPIO_DT_SPEC_GET(LED_RX, gpios);

// downlink callback
static void dl_callback(uint8_t port, bool data_pending, int16_t rssi, int8_t snr, uint8_t len, const uint8_t *data)
{
	printk("downlink data received: ");
    for(int8_t i=0; i < len; i++) {
		printk("%02X ", data[i]);
	}
    printk("\n");
	printk("port: %d, pending: %d, RSSI: %ddB, SNR: %dBm\n", port, data_pending, rssi, snr);
}

// ADR change callback
static void lorwan_datarate_changed(enum lorawan_datarate dr)
{
	uint8_t unused, max_size;

	lorawan_get_payload_sizes(&unused, &max_size);
	printk("new datarate: DR_%d, max payload: %d\n", dr, max_size);
}

//  ========== app_loarwan_init ============================================================
int8_t app_lorawan_init(void)
{
	struct lorawan_join_config join_cfg;
	static struct nvs_fs fs;
	uint16_t dev_nonce = 0u;

	int8_t itr = 1;
	uint8_t dev_eui[] 	= LORAWAN_DEV_EUI;
	uint8_t join_eui[]	= LORAWAN_JOIN_EUI;
	uint8_t app_key[]	= LORAWAN_APP_KEY;

	// initialize non-volatile storage (NVS) and read the current dev_nonce value
	app_flash_init(&fs);
	app_flash_init_param(&fs, NVS_DEVNONCE_ID, &dev_nonce);

	printk("starting LoRaWAN node initialization\n");

    // retrieve the LoRa SX1276 device
	const struct device *lora_dev = DEVICE_DT_GET(DT_ALIAS(lora0));
	if (!device_is_ready(lora_dev)) {
		printk("%s: LoRaWAN device not ready\n", lora_dev->name);
		return 0;
	}

	printk("starting LoRaWAN stack\n");

    // set the region (Europe)
	int8_t ret = lorawan_set_region(LORAWAN_REGION_EU868);
	if (ret < 0) {
		printk("failed to start LoRaWAN stack. error: %d\n", ret);
		return 0;
	}

	// indicate device activity by toggling the transmission LED
	gpio_pin_set_dt(&led_tx, 1);

	// start the LoRaWAN stack
	ret = lorawan_start();
	if (ret < 0) {
		printk("failed to start LoRaWAN stack. error: %d\n", ret);
		return 0;
	} else {
			// allow some time for the stack to stabilize
			k_sleep(K_MSEC(500));
	}

	// enable Adaptive Data Rate (ADR) to optimize communication settings
    lorawan_enable_adr(true);

    // register downlink and data rate change callbacks for receiving messages and updates
	struct lorawan_downlink_cb downlink_cb = {
		.port = LW_RECV_PORT_ANY,
		.cb = dl_callback
	};
	lorawan_register_downlink_callback(&downlink_cb);
	lorawan_register_dr_changed_callback(lorwan_datarate_changed);  

	// configuration of lorawan network using OTAA
    join_cfg.mode = LORAWAN_ACT_OTAA;
	join_cfg.dev_eui = dev_eui;
	join_cfg.otaa.join_eui = join_eui;
	join_cfg.otaa.app_key = app_key;
	join_cfg.otaa.nwk_key = app_key;
	join_cfg.otaa.dev_nonce = dev_nonce;

	// attempt to join the LoRaWAN network using OTAA
	do {
		printk("attempting to join LoRaWAN network using OTAA. Dev nonce: %d, attempt: %d\n", join_cfg.otaa.dev_nonce, itr++);

		// indicate receiving activity by toggling the reception LED
		gpio_pin_set_dt(&led_rx, 1);

		ret = lorawan_join(&join_cfg);
		if (ret < 0) {
			if (ret == -ETIMEDOUT) {
				printk("join request timed out. retrying...\n");
			} else {
				printk("failed to join network. error: %d\n", ret);
			}
		} else {
			printk("successfully joined LoRaWAN network using OTAA.\n");
		}

		// increment and save the device nonce in NVS for the next attempt
		dev_nonce++;
		join_cfg.otaa.dev_nonce = dev_nonce;

		// save value away in Non-Volatile Storage.
		ssize_t err = nvs_write(&fs, NVS_DEVNONCE_ID, &dev_nonce, sizeof(dev_nonce));
		if (err < 0) {
			printk("NVS: failed to write dev_nonce (id %d). error: %d\n", NVS_DEVNONCE_ID, err);
		}

		// if the join attempt failed, wait before retrying
		if (ret < 0) {
			// if failed, wait before re-trying.
			k_sleep(K_MSEC(10000));
		}
	} while (ret != 0 && itr < MAX_JOIN_ATTEMPTS);

	// turn off LEDs to indicate the end of the process
	gpio_pin_set_dt(&led_tx, 0);
	gpio_pin_set_dt(&led_rx, 0);
    return 1;
}
```

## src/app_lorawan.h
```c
/*
 * Copyright (c) 2025
 * Regis Rousseau
 * Univ Lyon, INSA Lyon, Inria, CITI, EA3720
 * SPDX-License-Identifier: Apache-2.0
 */

#ifndef APP_LORAWAN_H
#define APP_LORAWAN_H

//  ========== includes ====================================================================
#include <zephyr/kernel.h>
#include <zephyr/device.h>
#include <zephyr/devicetree.h>
#include <zephyr/drivers/gpio.h>
#include <zephyr/drivers/lora.h>
#include <zephyr/lorawan/lorawan.h>
#include <zephyr/random/random.h>

//  ========== defines =====================================================================
#define LED_TX                  DT_ALIAS(ledtx)     // declared in device tree 
#define LED_RX                  DT_ALIAS(ledrx)     // declared in device tree

// customize based on network configuration
#define LORAWAN_DEV_EUI			{ 0x70, 0xB3, 0xD5, 0x7E, 0xD0, 0x06, 0xB4, 0x66 } 

#define LORAWAN_JOIN_EUI		{ 0x00, 0x00, 0x00, 0x00, 0x00, 0x00, 0x00, 0x00 }
#define LORAWAN_APP_KEY			{ 0xC7, 0x32, 0x0F, 0x37, 0xFF, 0x62, 0xE0, 0xA8, 0x4E, 0x94, 0xC1, 0x9C, 0x27, 0x2B, 0xFA, 0x4C }
#define LORAWAN_PORT            2       // application port
#define MAX_JOIN_ATTEMPTS       10      // limiting join attempts

//  ========== prototypes ==================================================================
int8_t app_lorawan_init(void);
int app_lorawan_start_tx(void);
void app_lorawan_trigger_tx(void);
static void app_lorawan_thread(void *arg1, void *arg2, void *arg3);

#endif /* APP_LORAWAN_H */
```
